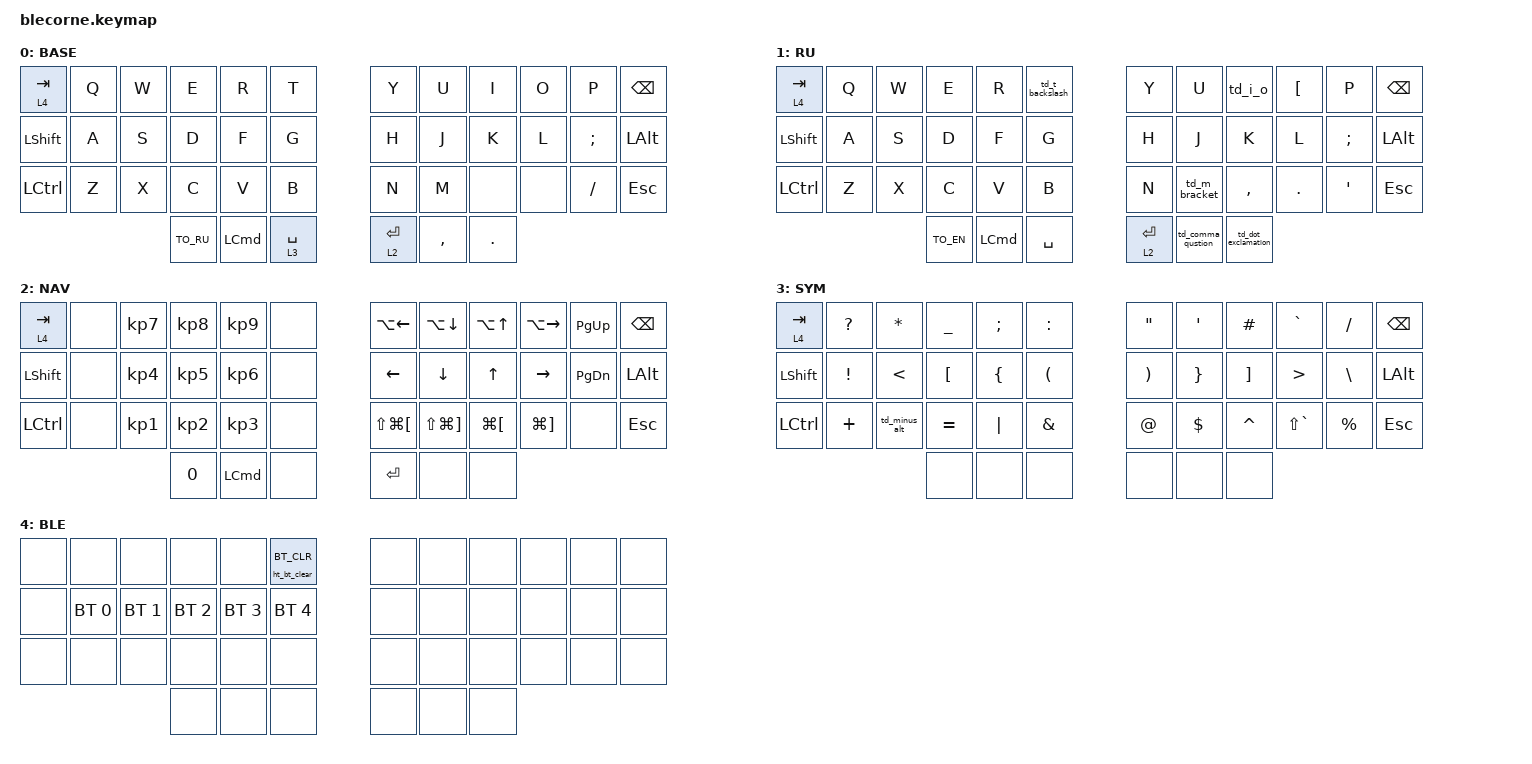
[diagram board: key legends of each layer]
/*
 * Copyright (c) 2020 The ZMK Contributors
 *
 * SPDX-License-Identifier: MIT
 */

#include <behaviors.dtsi>
#include <dt-bindings/zmk/bt.h>
#include <dt-bindings/zmk/keys.h>

/ {
    macros {
        TO_RU: switch_to_ru {
            compatible = "zmk,behavior-macro";
            #binding-cells = <0>;
            bindings = <&kp F18 &to 1>;
            label = "SWITCH_TO_RU";
        };

        TO_EN: switch_to_en {
            compatible = "zmk,behavior-macro";
            #binding-cells = <0>;
            bindings = <&kp F17 &to 0>;
            label = "SWITCH_TO_EN";
        };
    };

    behaviors {
        td_m_bracket: td_m_bracket {
            compatible = "zmk,behavior-tap-dance";
            #binding-cells = <0>;
            bindings = <&kp M>, <&kp RIGHT_BRACKET>;

            tapping-term-ms = <300>;
        };

        td_i_o: td_i_o {
            compatible = "zmk,behavior-tap-dance";
            #binding-cells = <0>;
            bindings = <&kp I>, <&kp O>;

            tapping-term-ms = <300>;
        };

        td_t_backslash: td_t_backslash {
            compatible = "zmk,behavior-tap-dance";
            #binding-cells = <0>;
            bindings = <&kp T>, <&kp BACKSLASH>;

            tapping-term-ms = <300>;
            label = "TD_T_BACKSLASH";
        };

        ht_mo_kp: ht_mo_kp {
            compatible = "zmk,behavior-hold-tap";
            bindings = <&mo>, <&kp>;

            #binding-cells = <2>;
            tapping-term-ms = <300>;
            flavor = "tap-preferred";
            label = "HT_MO_KP";
            require-prior-idle-ms = <150>;
        };

        ht_bt_clear: ht_bt_clear {
            compatible = "zmk,behavior-hold-tap";
            bindings = <&bt>, <&none>;

            #binding-cells = <2>;
            tapping-term-ms = <500>;
            flavor = "hold-preferred";
        };

        td_minus_alt: td_minus_alt {
            compatible = "zmk,behavior-tap-dance";
            #binding-cells = <0>;
            bindings = <&kp KP_MINUS>, <&kp LA(MINUS)>;

            tapping-term-ms = <300>;
        };

        td_comma_qustion: td_comma_qustion {
            compatible = "zmk,behavior-tap-dance";
            #binding-cells = <0>;
            bindings = <&kp LS(NUMBER_6)>, <&kp QUESTION>;

            tapping-term-ms = <300>;
            label = "TD_COMMA_QUSTION";
        };

        td_dot_exclamation: td_dot_exclamation {
            compatible = "zmk,behavior-tap-dance";
            #binding-cells = <0>;
            bindings = <&kp LS(N7)>, <&kp EXCLAMATION>;

            tapping-term-ms = <300>;
            label = "TD_DOT_EXCLAMATION";
        };
    };

    combos {
        compatible = "zmk,combos";

        minus {
            bindings = <&kp MINUS>;
            key-positions = <40 41>;
            layers = <1>;
            timeout-ms = <50>;
            require-prior-idle-ms = <150>;
        };
    };

    keymap {
        compatible = "zmk,keymap";

        BASE {
            bindings = <
&ht_mo_kp 4 TAB   &kp Q  &kp W  &kp E   &kp R             &kp T              &kp Y              &kp U      &kp I    &kp O  &kp P          &kp BSPC
&kp LEFT_SHIFT    &kp A  &kp S  &kp D   &kp F             &kp G              &kp H              &kp J      &kp K    &kp L  &kp SEMICOLON  &kp LEFT_ALT
&kp LEFT_CONTROL  &kp Z  &kp X  &kp C   &kp V             &kp B              &kp N              &kp M      &none    &none  &kp SLASH      &kp ESCAPE
                                &TO_RU  &kp LEFT_COMMAND  &ht_mo_kp 3 SPACE  &ht_mo_kp 2 ENTER  &kp COMMA  &kp DOT
            >;
        };

        RU {
            bindings = <
&ht_mo_kp 4 TAB   &kp Q  &kp W  &kp E   &kp R             &td_t_backslash  &kp Y              &kp U              &td_i_o              &kp LEFT_BRACKET  &kp P             &kp BACKSPACE
&kp LEFT_SHIFT    &kp A  &kp S  &kp D   &kp F             &kp G            &kp H              &kp J              &kp K                &kp L             &kp SEMICOLON     &kp LEFT_ALT
&kp LEFT_CONTROL  &kp Z  &kp X  &kp C   &kp V             &kp B            &kp N              &td_m_bracket      &kp COMMA            &kp DOT           &kp SINGLE_QUOTE  &kp ESCAPE
                                &TO_EN  &kp LEFT_COMMAND  &kp SPACE        &ht_mo_kp 2 ENTER  &td_comma_qustion  &td_dot_exclamation
            >;
        };

        NAV {
            bindings = <
&ht_mo_kp 4 TAB   &none  &kp KP_N7        &kp KP_N8     &kp KP_N9         &none  &kp LA(LEFT)              &kp LA(DOWN)               &kp LA(UP)            &kp LA(RIGHT)          &kp PG_UP      &kp BSPC
&kp LEFT_SHIFT    &none  &kp KP_NUMBER_4  &kp KP_N5     &kp KP_N6         &none  &kp LEFT                  &kp DOWN                   &kp UP                &kp RIGHT              &kp PAGE_DOWN  &kp LEFT_ALT
&kp LEFT_CONTROL  &none  &kp KP_N1        &kp KP_N2     &kp KP_NUMBER_3   &none  &kp LS(LG(LEFT_BRACKET))  &kp LS(LG(RIGHT_BRACKET))  &kp LG(LEFT_BRACKET)  &kp LG(RIGHT_BRACKET)  &none          &kp ESCAPE
                                          &kp NUMBER_0  &kp LEFT_COMMAND  &none  &kp ENTER                 &none                      &none
            >;
        };

        SYM {
            bindings = <
&ht_mo_kp 4 TAB   &kp QUESTION     &kp ASTERISK   &kp UNDERSCORE    &kp SEMICOLON   &kp COLON             &kp DOUBLE_QUOTES      &kp SINGLE_QUOTE  &kp HASH           &kp GRAVE         &kp SLASH      &kp BSPC
&kp LEFT_SHIFT    &kp EXCLAMATION  &kp LESS_THAN  &kp LEFT_BRACKET  &kp LEFT_BRACE  &kp LEFT_PARENTHESIS  &kp RIGHT_PARENTHESIS  &kp RIGHT_BRACE   &kp RIGHT_BRACKET  &kp GREATER_THAN  &kp BACKSLASH  &kp LEFT_ALT
&kp LEFT_CONTROL  &kp PLUS         &td_minus_alt  &kp EQUAL         &kp PIPE        &kp AMPERSAND         &kp AT_SIGN            &kp DOLLAR        &kp CARET          &kp LS(GRAVE)     &kp PERCENT    &kp ESCAPE
                                                  &none             &none           &none                 &none                  &none             &none
            >;
        };

        BLE {
            bindings = <
&none  &none         &none         &none         &none         &ht_bt_clear BT_CLR  &none  &none  &none  &none  &none  &none
&none  &bt BT_SEL 0  &bt BT_SEL 1  &bt BT_SEL 2  &bt BT_SEL 3  &bt BT_SEL 4         &none  &none  &none  &none  &none  &none
&none  &none         &none         &none         &none         &none                &none  &none  &none  &none  &none  &none
                                   &none         &none         &none                &none  &none  &none
            >;
        };
    };
};
